AUTOSAR XML (schema 3-1-5)
package /led_rte_mpc5567_system/BlinkerKit
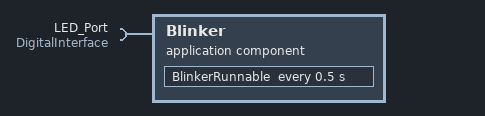
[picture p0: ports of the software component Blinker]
  application software component type Blinker
    require port LED_Port: required-interface=DigitalInterface
  internal behavior BlinkerBehavior: component=Blinker
    timing event Blinker_timingEvent: start-on-event=BlinkerRunnable, period=0.5
    runnable BlinkerRunnable: can-be-invoked-concurrently=true
      sync call LED_Port_CallPoint: operation=LED_Port.Write
  swc implementation BlinkerImplementation: behavior=BlinkerBehavior
